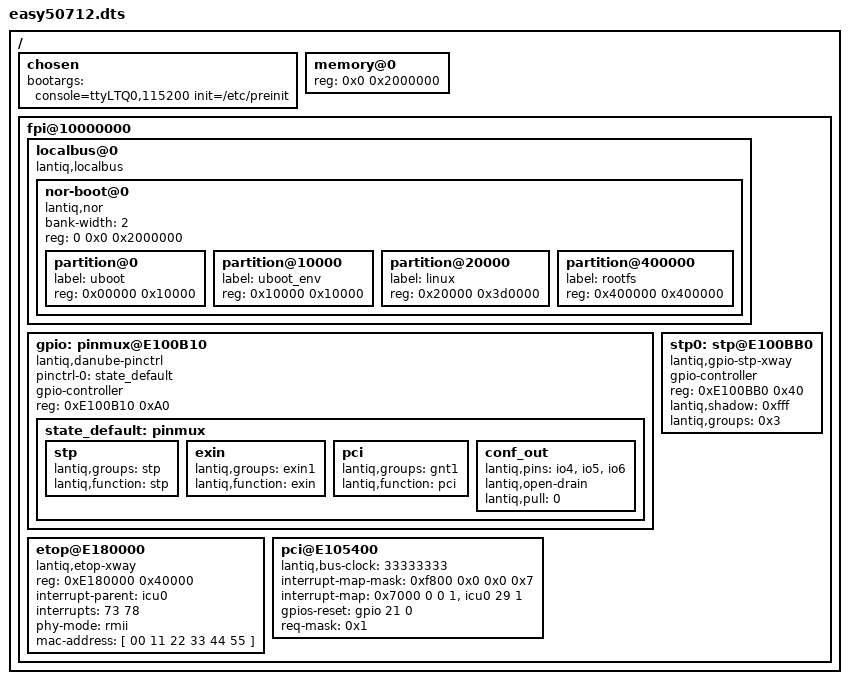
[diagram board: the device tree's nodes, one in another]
// SPDX-License-Identifier: GPL-2.0
/dts-v1/;

/include/ "danube.dtsi"

/ {
	chosen {
		bootargs = "console=ttyLTQ0,115200 init=/etc/preinit";
	};

	memory@0 {
		device_type = "memory";
		reg = <0x0 0x2000000>;
	};

	fpi@10000000 {
		#address-cells = <1>;
		#size-cells = <1>;
		localbus@0 {
			#address-cells = <2>;
			#size-cells = <1>;
			ranges = <0 0 0x0 0x3ffffff /* addrsel0 */
				1 0 0x4000000 0x4000010>; /* addsel1 */
			compatible = "lantiq,localbus", "simple-bus";

			nor-boot@0 {
				compatible = "lantiq,nor";
				bank-width = <2>;
				reg = <0 0x0 0x2000000>;
				#address-cells = <1>;
				#size-cells = <1>;

				partition@0 {
					label = "uboot";
					reg = <0x00000 0x10000>; /* 64 KB */
				};

				partition@10000 {
					label = "uboot_env";
					reg = <0x10000 0x10000>; /* 64 KB */
				};

				partition@20000 {
					label = "linux";
					reg = <0x20000 0x3d0000>;
				};

				partition@400000 {
					label = "rootfs";
					reg = <0x400000 0x400000>;
				};
			};
		};

		gpio: pinmux@E100B10 {
			compatible = "lantiq,danube-pinctrl";
			pinctrl-names = "default";
			pinctrl-0 = <&state_default>;

			#gpio-cells = <2>;
			gpio-controller;
			reg = <0xE100B10 0xA0>;

			state_default: pinmux {
				stp {
					lantiq,groups = "stp";
					lantiq,function = "stp";
				};
				exin {
					lantiq,groups = "exin1";
					lantiq,function = "exin";
				};
				pci {
					lantiq,groups = "gnt1";
					lantiq,function = "pci";
				};
				conf_out {
					lantiq,pins = "io4", "io5", "io6"; /* stp */
					lantiq,open-drain;
					lantiq,pull = <0>;
				};
			};
		};

		etop@E180000 {
			compatible = "lantiq,etop-xway";
			reg = <0xE180000 0x40000>;
			interrupt-parent = <&icu0>;
			interrupts = <73 78>;
			phy-mode = "rmii";
			mac-address = [ 00 11 22 33 44 55 ];
		};

		stp0: stp@E100BB0 {
			#gpio-cells = <2>;
			compatible = "lantiq,gpio-stp-xway";
			gpio-controller;
			reg = <0xE100BB0 0x40>;

			lantiq,shadow = <0xfff>;
			lantiq,groups = <0x3>;
		};

		pci@E105400 {
			lantiq,bus-clock = <33333333>;
			interrupt-map-mask = <0xf800 0x0 0x0 0x7>;
			interrupt-map = <
				0x7000 0 0 1 &icu0 29 1 // slot 14, irq 29
			>;
			gpios-reset = <&gpio 21 0>;
			req-mask = <0x1>;		/* GNT1 */
		};

	};
};
